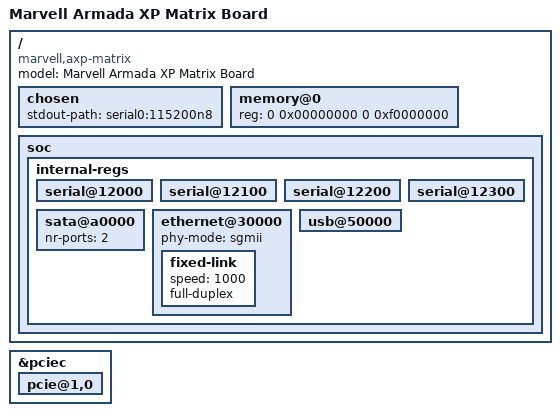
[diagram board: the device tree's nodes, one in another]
/dts-v1/;
#include "armada-xp-mv78460.dtsi"
/ {
	model = "Marvell Armada XP Matrix Board";
	compatible = "marvell,axp-matrix", "marvell,armadaxp-mv78460", "marvell,armadaxp", "marvell,armada-370-xp";
	chosen {
		stdout-path = "serial0:115200n8";
	};
	memory@0 {
		device_type = "memory";
		reg = <0 0x00000000 0 0xf0000000>;
	};
	soc {
		ranges = <MBUS_ID(0xf0, 0x01) 0 0 0xf1000000 0x100000
			  MBUS_ID(0x01, 0x1d) 0 0 0xfff00000 0x100000
			  MBUS_ID(0x09, 0x09) 0 0 0xf1100000 0x10000
			  MBUS_ID(0x09, 0x05) 0 0 0xf1110000 0x10000>;
		internal-regs {
			serial@12000 {
				status = "okay";
			};
			serial@12100 {
				status = "okay";
			};
			serial@12200 {
				status = "okay";
			};
			serial@12300 {
				status = "okay";
			};
			sata@a0000 {
				nr-ports = <2>;
				status = "okay";
			};
			ethernet@30000 {
				status = "okay";
				phy-mode = "sgmii";
				fixed-link {
					speed = <1000>;
					full-duplex;
				};
			};
			usb@50000 {
				status = "okay";
			};
		};
	};
};
&pciec {
	status = "okay";
	pcie@1,0 {
		status = "okay";
	};
};
